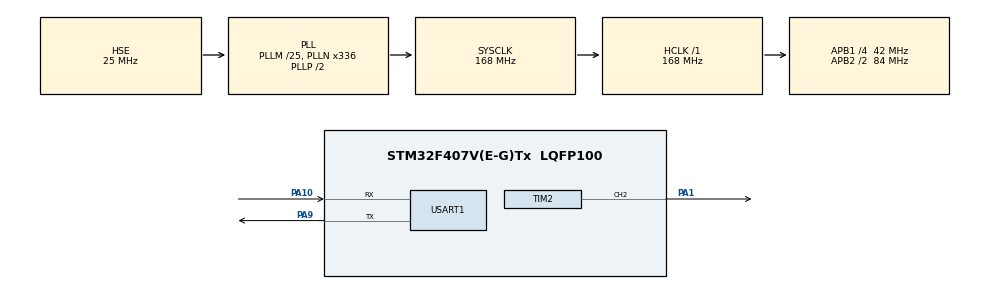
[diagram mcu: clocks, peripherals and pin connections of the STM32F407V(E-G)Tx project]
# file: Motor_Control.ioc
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Mcu.Family=STM32F4
Mcu.Name=STM32F407V(E-G)Tx
Mcu.Package=LQFP100
NVIC.PriorityGroup=NVIC_PRIORITYGROUP_4
NVIC.USART1_IRQn=true\:0\:0\:false\:false\:true\:true\:true\:true
PA1.Signal=S_TIM2_CH2
PA10.Mode=Asynchronous
PA10.Signal=USART1_RX
PA9.Mode=Asynchronous
PA9.Signal=USART1_TX
PH0-OSC_IN.Mode=HSE-External-Oscillator
PH0-OSC_IN.Signal=RCC_OSC_IN
PH1-OSC_OUT.Mode=HSE-External-Oscillator
PH1-OSC_OUT.Signal=RCC_OSC_OUT
ProjectManager.HeapSize=0x200
ProjectManager.StackSize=0x400
ProjectManager.TargetToolchain=CMake
RCC.48MHZClocksFreq_Value=84000000
RCC.AHBFreq_Value=168000000
RCC.APB1CLKDivider=RCC_HCLK_DIV4
RCC.APB1Freq_Value=42000000
RCC.APB1TimFreq_Value=84000000
RCC.APB2CLKDivider=RCC_HCLK_DIV2
RCC.APB2Freq_Value=84000000
RCC.APB2TimFreq_Value=168000000
RCC.CortexFreq_Value=168000000
RCC.HCLKFreq_Value=168000000
RCC.HSE_VALUE=25000000
RCC.HSI_VALUE=16000000
RCC.LSE_VALUE=32768
RCC.PLLM=25
RCC.PLLN=336
RCC.PLLSourceVirtual=RCC_PLLSOURCE_HSE
RCC.SYSCLKFreq_VALUE=168000000
RCC.SYSCLKSource=RCC_SYSCLKSOURCE_PLLCLK
RCC.VCOOutputFreq_Value=336000000
SH.S_TIM2_CH2.0=TIM2_CH2,PWM Generation2 CH2
TIM2.Channel-PWM\ Generation2\ CH2=TIM_CHANNEL_2
TIM2.Period=19999
TIM2.Prescaler=83
USART1.VirtualMode=VM_ASYNC
board=custom

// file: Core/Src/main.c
/* USER CODE BEGIN Header */
/**
  ******************************************************************************
  * @file           : main.c
  * @brief          : Main program body
  ******************************************************************************
  * @attention
  *
  * Copyright (c) 2026 STMicroelectronics.
  * All rights reserved.
  *
  * This software is licensed under terms that can be found in the LICENSE file
  * in the root directory of this software component.
  * If no LICENSE file comes with this software, it is provided AS-IS.
  *
  ******************************************************************************
  */
/* USER CODE END Header */
#include "main.h"

/* USER CODE BEGIN Includes */
#include <stdio.h>
#include <string.h>
/* USER CODE END Includes */

TIM_HandleTypeDef htim2;

UART_HandleTypeDef huart1;

/* USER CODE BEGIN PV */
uint8_t rx_buffer[1];   // 接收1个字节
int current_pwm = 500;  // 当前角度(脉宽)
int target_pwm = 500;   // 目标角度(脉宽)
/* USER CODE END PV */

void SystemClock_Config(void);
static void MX_GPIO_Init(void);
static void MX_TIM2_Init(void);
static void MX_USART1_UART_Init(void);

/* USER CODE BEGIN 0 */
void HAL_UART_RxCpltCallback(UART_HandleTypeDef *huart)
{
    // 如果是串口1来的数据
    if(huart->Instance == USART1)
    {
        uint8_t angle = rx_buffer[0]; // 拿到收到的角度 (0~180)

        // 只有合理角度才执行
        if(angle <= 180)
        {
            // 映射公式：把 0~180度 映射成 500~2500脉宽
            target_pwm = 500 + (angle * 2000 / 180);

            // (可选) 发个回声给电脑，确认收到了
            char msg[32];
            sprintf(msg, "STM32 Get: %d\r\n", angle);
            HAL_UART_Transmit(&huart1, (uint8_t*)msg, strlen(msg), 10);
        }

        // 重新开启监听，准备收下一个字（这就叫非阻塞）
        HAL_UART_Receive_IT(&huart1, rx_buffer, 1);
    }
}
/* USER CODE END 0 */

int main(void)
{

  /* MCU Configuration--------------------------------------------------------*/

  /* Reset of all peripherals, Initializes the Flash interface and the Systick. */
  HAL_Init();

  /* Configure the system clock */
  SystemClock_Config();

  /* Initialize all configured peripherals */
  MX_GPIO_Init();
  MX_TIM2_Init();
  MX_USART1_UART_Init();
  /* USER CODE BEGIN 2 */
  HAL_TIM_PWM_Start(&htim2, TIM_CHANNEL_2); // 启动电机
  HAL_UART_Receive_IT(&huart1, rx_buffer, 1); // 启动串口监听
  /* USER CODE END 2 */

  /* Infinite loop */
  while (1)
  {

    /* USER CODE BEGIN 3 */
    // 这是一个简单的“软启动”逻辑，让舵机慢慢转过去，防止电流过大
    if (current_pwm < target_pwm)
    {
        current_pwm += 10; // 每次加一点
        if(current_pwm > target_pwm) current_pwm = target_pwm;
    }
    else if (current_pwm > target_pwm)
    {
        current_pwm -= 10; // 每次减一点
        if(current_pwm < target_pwm) current_pwm = target_pwm;
    }

    // 更新舵机位置
    __HAL_TIM_SET_COMPARE(&htim2, TIM_CHANNEL_2, current_pwm);

    // 这里的延时决定了转速，越小转得越快
    HAL_Delay(10);
    /* USER CODE END 3 */
  }
}

void SystemClock_Config(void)
{
  RCC_OscInitTypeDef RCC_OscInitStruct = {0};
  RCC_ClkInitTypeDef RCC_ClkInitStruct = {0};

  /** Configure the main internal regulator output voltage
  */
  __HAL_RCC_PWR_CLK_ENABLE();
  __HAL_PWR_VOLTAGESCALING_CONFIG(PWR_REGULATOR_VOLTAGE_SCALE1);

  /** Initializes the RCC Oscillators according to the specified parameters
  * in the RCC_OscInitTypeDef structure.
  */
  RCC_OscInitStruct.OscillatorType = RCC_OSCILLATORTYPE_HSE;
  RCC_OscInitStruct.HSEState = RCC_HSE_ON;
  RCC_OscInitStruct.PLL.PLLState = RCC_PLL_ON;
  RCC_OscInitStruct.PLL.PLLSource = RCC_PLLSOURCE_HSE;
  RCC_OscInitStruct.PLL.PLLM = 25;
  RCC_OscInitStruct.PLL.PLLN = 336;
  RCC_OscInitStruct.PLL.PLLP = RCC_PLLP_DIV2;
  RCC_OscInitStruct.PLL.PLLQ = 4;
  if (HAL_RCC_OscConfig(&RCC_OscInitStruct) != HAL_OK)
  {
    Error_Handler();
  }

  /** Initializes the CPU, AHB and APB buses clocks
  */
  RCC_ClkInitStruct.ClockType = RCC_CLOCKTYPE_HCLK|RCC_CLOCKTYPE_SYSCLK
                              |RCC_CLOCKTYPE_PCLK1|RCC_CLOCKTYPE_PCLK2;
  RCC_ClkInitStruct.SYSCLKSource = RCC_SYSCLKSOURCE_PLLCLK;
  RCC_ClkInitStruct.AHBCLKDivider = RCC_SYSCLK_DIV1;
  RCC_ClkInitStruct.APB1CLKDivider = RCC_HCLK_DIV4;
  RCC_ClkInitStruct.APB2CLKDivider = RCC_HCLK_DIV2;

  if (HAL_RCC_ClockConfig(&RCC_ClkInitStruct, FLASH_LATENCY_5) != HAL_OK)
  {
    Error_Handler();
  }
}

static void MX_TIM2_Init(void)
{

  TIM_MasterConfigTypeDef sMasterConfig = {0};
  TIM_OC_InitTypeDef sConfigOC = {0};

  htim2.Instance = TIM2;
  htim2.Init.Prescaler = 83;
  htim2.Init.CounterMode = TIM_COUNTERMODE_UP;
  htim2.Init.Period = 19999;
  htim2.Init.ClockDivision = TIM_CLOCKDIVISION_DIV1;
  htim2.Init.AutoReloadPreload = TIM_AUTORELOAD_PRELOAD_DISABLE;
  if (HAL_TIM_PWM_Init(&htim2) != HAL_OK)
  {
    Error_Handler();
  }
  sMasterConfig.MasterOutputTrigger = TIM_TRGO_RESET;
  sMasterConfig.MasterSlaveMode = TIM_MASTERSLAVEMODE_DISABLE;
  if (HAL_TIMEx_MasterConfigSynchronization(&htim2, &sMasterConfig) != HAL_OK)
  {
    Error_Handler();
  }
  sConfigOC.OCMode = TIM_OCMODE_PWM1;
  sConfigOC.Pulse = 0;
  sConfigOC.OCPolarity = TIM_OCPOLARITY_HIGH;
  sConfigOC.OCFastMode = TIM_OCFAST_DISABLE;
  if (HAL_TIM_PWM_ConfigChannel(&htim2, &sConfigOC, TIM_CHANNEL_2) != HAL_OK)
  {
    Error_Handler();
  }
  HAL_TIM_MspPostInit(&htim2);

}

static void MX_USART1_UART_Init(void)
{

  huart1.Instance = USART1;
  huart1.Init.BaudRate = 115200;
  huart1.Init.WordLength = UART_WORDLENGTH_8B;
  huart1.Init.StopBits = UART_STOPBITS_1;
  huart1.Init.Parity = UART_PARITY_NONE;
  huart1.Init.Mode = UART_MODE_TX_RX;
  huart1.Init.HwFlowCtl = UART_HWCONTROL_NONE;
  huart1.Init.OverSampling = UART_OVERSAMPLING_16;
  if (HAL_UART_Init(&huart1) != HAL_OK)
  {
    Error_Handler();
  }

}

static void MX_GPIO_Init(void)
{

  /* GPIO Ports Clock Enable */
  __HAL_RCC_GPIOH_CLK_ENABLE();
  __HAL_RCC_GPIOA_CLK_ENABLE();

}

void Error_Handler(void)
{
  __disable_irq();
  while (1)
  {
  }
}
